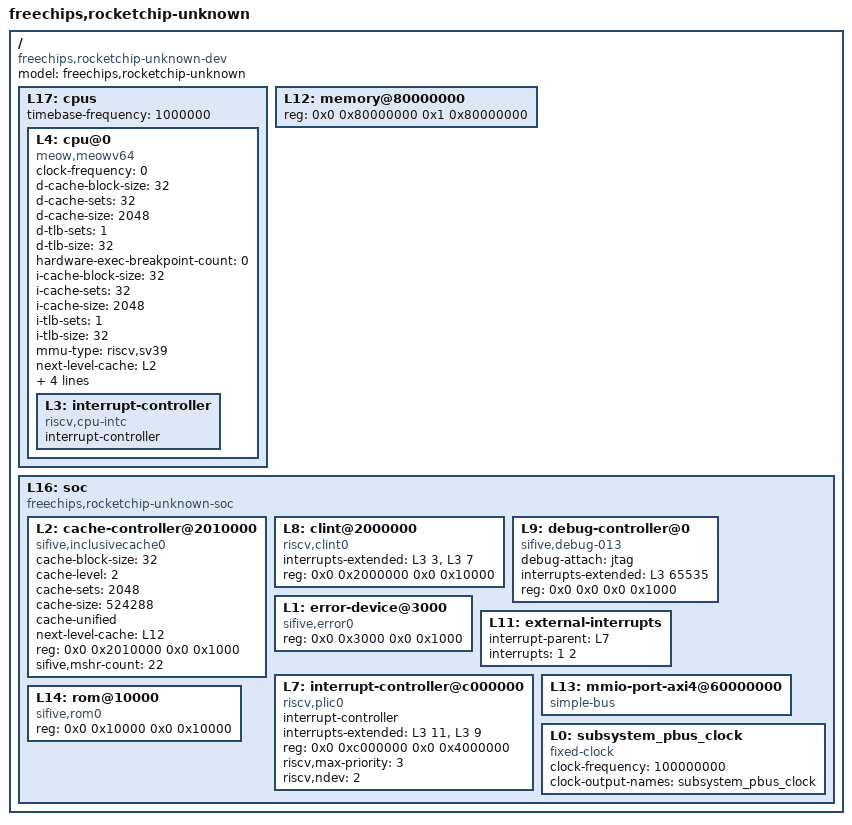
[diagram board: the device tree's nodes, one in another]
/dts-v1/;

/ {
	#address-cells = <2>;
	#size-cells = <2>;
	compatible = "freechips,rocketchip-unknown-dev";
	model = "freechips,rocketchip-unknown";
	L17: cpus {
		#address-cells = <1>;
		#size-cells = <0>;
		timebase-frequency = <1000000>;
		L4: cpu@0 {
			clock-frequency = <0>;
			compatible = "meow,meowv64", "riscv";
			d-cache-block-size = <32>;
			d-cache-sets = <32>;
			d-cache-size = <2048>;
			d-tlb-sets = <1>;
			d-tlb-size = <32>;
			device_type = "cpu";
			hardware-exec-breakpoint-count = <0>;
			i-cache-block-size = <32>;
			i-cache-sets = <32>;
			i-cache-size = <2048>;
			i-tlb-sets = <1>;
			i-tlb-size = <32>;
			mmu-type = "riscv,sv39";
			next-level-cache = <&L2>;
			reg = <0x0>;
			riscv,isa = "rv64imafdcv";
			status = "okay";
			timebase-frequency = <1000000>;
			tlb-split;
			L3: interrupt-controller {
				#interrupt-cells = <1>;
				compatible = "riscv,cpu-intc";
				interrupt-controller;
			};
		};
	};
	L12: memory@80000000 {
		device_type = "memory";
		reg = <0x0 0x80000000 0x1 0x80000000>;
	};
	L16: soc {
		#address-cells = <2>;
		#size-cells = <2>;
		compatible = "freechips,rocketchip-unknown-soc", "simple-bus";
		ranges;
		L2: cache-controller@2010000 {
			cache-block-size = <32>;
			cache-level = <2>;
			cache-sets = <2048>;
			cache-size = <524288>;
			cache-unified;
			compatible = "sifive,inclusivecache0", "cache";
			next-level-cache = <&L12>;
			reg = <0x0 0x2010000 0x0 0x1000>;
			reg-names = "control";
			sifive,mshr-count = <22>;
		};
		L8: clint@2000000 {
			compatible = "riscv,clint0";
			interrupts-extended = <&L3 3 &L3 7>;
			reg = <0x0 0x2000000 0x0 0x10000>;
			reg-names = "control";
		};
		L9: debug-controller@0 {
			compatible = "sifive,debug-013", "riscv,debug-013";
			debug-attach = "jtag";
			interrupts-extended = <&L3 65535>;
			reg = <0x0 0x0 0x0 0x1000>;
			reg-names = "control";
		};
		L1: error-device@3000 {
			compatible = "sifive,error0";
			reg = <0x0 0x3000 0x0 0x1000>;
		};
		L11: external-interrupts {
			interrupt-parent = <&L7>;
			interrupts = <1 2>;
		};
		L7: interrupt-controller@c000000 {
			#interrupt-cells = <1>;
			compatible = "riscv,plic0";
			interrupt-controller;
			interrupts-extended = <&L3 11 &L3 9>;
			reg = <0x0 0xc000000 0x0 0x4000000>;
			reg-names = "control";
			riscv,max-priority = <3>;
			riscv,ndev = <2>;
		};
		L13: mmio-port-axi4@60000000 {
			#address-cells = <2>;
			#size-cells = <1>;
			compatible = "simple-bus";
			ranges = <0x0 0x60000000 0x0 0x60000000 0x20000000 0x2 0x0 0x2 0x0 0x0>;
		};
		L14: rom@10000 {
			compatible = "sifive,rom0";
			reg = <0x0 0x10000 0x0 0x10000>;
			reg-names = "mem";
		};
		L0: subsystem_pbus_clock {
			#clock-cells = <0>;
			clock-frequency = <100000000>;
			clock-output-names = "subsystem_pbus_clock";
			compatible = "fixed-clock";
		};
	};
};
